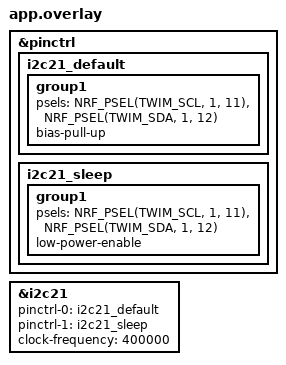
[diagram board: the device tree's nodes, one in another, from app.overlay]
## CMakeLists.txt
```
cmake_minimum_required(VERSION 3.20.0)

# Apply the device-tree overlay that enables I2C20 on P1.2/P1.3
list(APPEND EXTRA_DTC_OVERLAY_FILE "${CMAKE_CURRENT_SOURCE_DIR}/app.overlay")

find_package(Zephyr REQUIRED HINTS $ENV{ZEPHYR_BASE})

project(ThermalCam)

target_sources(app PRIVATE
  src/main.c
  src/mlx90640_api.c
  src/mlx90640_i2c.c
  src/ble_stream.c
)
```

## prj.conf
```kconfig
# UART logging — immediate (synchronous) mode prevents dropped messages
# when many lines are emitted back-to-back (e.g. the 31-line image frame).
CONFIG_LOG=y
CONFIG_LOG_BACKEND_UART=y
CONFIG_LOG_DEFAULT_LEVEL=4
CONFIG_LOG_MODE_IMMEDIATE=y

# Suppress noisy kernel mutex/scheduler debug traces from the 'os' module.
CONFIG_LOG_OVERRIDE_LEVEL=0
CONFIG_KERNEL_LOG_LEVEL_WRN=y

# Suppress BT stack / HCI / SoftDevice Controller debug traces.
CONFIG_BT_HCI_CORE_LOG_LEVEL_WRN=y
CONFIG_BT_HCI_DRIVER_LOG_LEVEL_WRN=y
CONFIG_BT_LOG_LEVEL_WRN=y

# Suppress CRACEN crypto driver power-on/off debug traces.
CONFIG_CRACEN_LOG_LEVEL_WRN=y

# GPIO for LED indicators
CONFIG_GPIO=y

# I2C driver for MLX90640
CONFIG_I2C=y

# Floating-point support (Cortex-M33 FPU)
CONFIG_FPU=y
CONFIG_FPU_SHARING=y

# Enable %f / %.1f in LOG_INF and printk
CONFIG_CBPRINTF_FP_SUPPORT=y

# ── BLE Nordic UART Service (NUS) ─────────────────────────────────────────
# BLE stack — Peripheral role (advertise + accept connections)
CONFIG_BT=y
CONFIG_BT_PERIPHERAL=y
CONFIG_BT_DEVICE_NAME="ThermalCam"
CONFIG_BT_DEVICE_APPEARANCE=0

# Nordic UART Service
CONFIG_BT_NUS=y

# Data Length Extension: up to 251-byte LL payload → 244-byte ATT payload
# This reduces the number of notifications per frame from 39 to 4.
CONFIG_BT_CTLR_DATA_LENGTH_MAX=251
CONFIG_BT_L2CAP_TX_MTU=247
CONFIG_BT_BUF_ACL_RX_SIZE=255
CONFIG_BT_BUF_ACL_TX_SIZE=255

# BLE callbacks run on the system workqueue — give it more stack
CONFIG_SYSTEM_WORKQUEUE_STACK_SIZE=4096
```

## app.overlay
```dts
/* Device tree overlay for ThermalCam on nRF54L15 DK (Nordic Semiconductor).
 *
 * Enables the I2C21 (TWIM1) peripheral on:
 *   SCL = P1.11
 *   SDA = P1.12
 *
 * Pin selection rationale (nRF54L15 DK):
 *   P0.0-P0.3  = UART30 (second UART)
 *   P0.4       = button3 / GRTC
 *   P1.4-P1.7  = UART20 (console)
 *   P1.8       = button2 / GRTC clkout
 *   P1.9       = button1
 *   P1.10      = LED1 / PWM20
 *   P1.13      = button0
 *   P1.14      = LED3
 *   P2.1/2/4   = SPI00 (NOR flash)
 *   P2.5       = SPI CS
 *   P2.7/2.9   = LEDs
 *   P1.2/P1.3  = ETM trace (TRACEDATA[2:3]) — require PCB modification
 *   P1.11/P1.12 = free general-purpose header pins, no board hardware attached
 *
 * The MLX90640 sensor is wired to these pins at I2C address 0x33.
 */

&pinctrl {
	i2c21_default: i2c21_default {
		group1 {
			psels = <NRF_PSEL(TWIM_SCL, 1, 11)>,
			        <NRF_PSEL(TWIM_SDA, 1, 12)>;
			bias-pull-up;
		};
	};

	i2c21_sleep: i2c21_sleep {
		group1 {
			psels = <NRF_PSEL(TWIM_SCL, 1, 11)>,
			        <NRF_PSEL(TWIM_SDA, 1, 12)>;
			low-power-enable;
		};
	};
};

&i2c21 {
	status = "okay";
	pinctrl-0 = <&i2c21_default>;
	pinctrl-1 = <&i2c21_sleep>;
	pinctrl-names = "default", "sleep";
	clock-frequency = <400000>;
};
```

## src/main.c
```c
/**
 * ThermalCam — MLX90640 thermal imaging on nRF54L15.
 *
 * Wiring: I2C20 on P1.2 (SCL) / P1.3 (SDA).  See app.overlay.
 * Sensor I2C address: 0x33 (MLX90640 default).
 *
 * The main() function configures the sensor once, then starts a periodic
 * thread that reads a thermal frame every MLX90640_READ_INTERVAL_S seconds
 * and renders it as an ASCII heat map on the RTT log.
 */

#include <zephyr/kernel.h>
#include <zephyr/device.h>
#include <zephyr/drivers/gpio.h>
#include <zephyr/logging/log.h>

#include "mlx90640_api.h"
#include "mlx90640_i2c.h"
#include "ble_stream.h"

LOG_MODULE_REGISTER(main, LOG_LEVEL_DBG);

/* The devicetree node identifier for the "led0"  and "led1" alias. */
#define LED0_NODE DT_ALIAS(led0)
#define LED1_NODE DT_ALIAS(led1)
#define LED2_NODE DT_ALIAS(led2)
#define LED3_NODE DT_ALIAS(led3)

/* ---- LED indicators ---- */
static const struct gpio_dt_spec s_led2 = GPIO_DT_SPEC_GET(LED2_NODE, gpios);
static const struct gpio_dt_spec s_led3 = GPIO_DT_SPEC_GET(LED3_NODE, gpios);

/* ---- Sensor settings ---- */
#define MLX90640_ADDR           0x33    /* Default 7-bit I2C address */
#define MLX90640_EMISSIVITY     0.95f   /* Typical for most surfaces */
#define MLX90640_TA_SHIFT       8.0f    /* °C shift applied to Ta for TR */
#define MLX90640_REFRESH_RATE    0x03    /* 4 Hz (register value) */
#define MLX90640_READ_INTERVAL_MS 500    /* Milliseconds between frame captures (2 fps) */

/* ---- Image geometry ---- */
#define MLX90640_ROWS    24
#define MLX90640_COLS    32
#define MLX90640_PIXELS  (MLX90640_ROWS * MLX90640_COLS)  /* 768 */

/*
 * Large buffers are static/global to keep them off the thread stack.
 * Combined they consume ~9.5 KB of BSS.
 */
static uint16_t       s_ee_data[832];
static uint16_t       s_frame_data[834];
static float          s_temp_image[MLX90640_PIXELS];
static paramsMLX90640 s_mlx90640_params;

/* ---- Thermal thread ---- */
#define THERMAL_STACK_SIZE  8192
#define THERMAL_PRIORITY    5

K_THREAD_STACK_DEFINE(s_thermal_stack, THERMAL_STACK_SIZE);
static struct k_thread s_thermal_thread;

/*
 * 7-level thermal palette — cold to hot:
 *   ' '  background / very cold
 *   '.'  cool
 *   '+'  below ambient
 *   '*'  near ambient
 *   'o'  warm
 *   '#'  hot
 *   '@'  very hot
 */
static const char ASCII_PALETTE[] = " .+*o#@";
#define ASCII_LEVELS ((int)(sizeof(ASCII_PALETTE) - 1))  /* 7 */

/* ============================================================
 * mlx90640_configure
 *
 * Obtains the I2C20 device, initialises the low-level driver,
 * dumps the sensor EEPROM, extracts calibration data, and sets
 * the refresh rate.
 *
 * Returns 0 on success, negative errno on failure.
 * ============================================================ */
static int mlx90640_configure(void)
{
    const struct device *i2c_dev = DEVICE_DT_GET(DT_NODELABEL(i2c21));

    if (!device_is_ready(i2c_dev)) {
        LOG_ERR("I2C21 device not ready");
        return -ENODEV;
    }

    MLX90640_I2CInit(i2c_dev);
    LOG_INF("I2C21 initialised (SCL=P1.11 SDA=P1.12, 400 kHz)");

    /* Read the 832-word factory calibration EEPROM. */
    int ret = MLX90640_DumpEE(MLX90640_ADDR, s_ee_data);
    if (ret != 0) {
        LOG_ERR("Failed to dump EEPROM (err %d)", ret);
        return ret;
    }
    LOG_INF("EEPROM read OK");

    /* Parse EEPROM into per-pixel calibration parameters. */
    ret = MLX90640_ExtractParameters(s_ee_data, &s_mlx90640_params);
    if (ret != 0) {
        LOG_ERR("Parameter extraction failed (err %d)", ret);
        return ret;
    }
    LOG_INF("Calibration parameters extracted");

    /* Set hardware refresh rate to 16 Hz (register value 0x05). */
    ret = MLX90640_SetRefreshRate(MLX90640_ADDR, MLX90640_REFRESH_RATE);
    if (ret != 0) {
        LOG_ERR("Failed to set refresh rate (err %d)", ret);
        return ret;
    }
    LOG_INF("MLX90640 configured: 4 Hz refresh, emissivity=0.95");

    return 0;
}

/* ============================================================
 * mlx90640_read_image
 *
 * Reads two consecutive sub-frames (interleaved/chess mode).
 * After both sub-frames, s_temp_image[] holds temperatures for
 * all 768 pixels (24 rows × 32 columns), in °C.
 *
 * Returns 0 on success, negative on I2C or sensor error.
 * ============================================================ */
#define SUBFRAME_MAX_RETRIES  3

static int mlx90640_read_image(void)
{
    for (int subframe = 0; subframe < 2; subframe++) {
        int ret = -1;

        for (int attempt = 0; attempt < SUBFRAME_MAX_RETRIES; attempt++) {
            ret = MLX90640_GetFrameData(MLX90640_ADDR, s_frame_data);
            if (ret >= 0) {
                break;  /* success */
            }
            LOG_WRN("GetFrameData failed (sub %d, attempt %d, err %d)",
                    subframe, attempt, ret);

            /* Try to unstick the I2C bus before retrying. */
            (void)MLX90640_I2CRecover();
            k_msleep(50);
        }

        if (ret < 0) {
            LOG_ERR("GetFrameData failed after %d retries (sub %d, err %d)",
                    SUBFRAME_MAX_RETRIES, subframe, ret);
            return ret;
        }

        float vdd = MLX90640_GetVdd(s_frame_data, &s_mlx90640_params);
        float ta  = MLX90640_GetTa(s_frame_data,  &s_mlx90640_params);
        float tr  = ta - MLX90640_TA_SHIFT;   /* reflected temperature */

        MLX90640_CalculateTo(s_frame_data, &s_mlx90640_params,
                             MLX90640_EMISSIVITY, tr, s_temp_image);

        LOG_DBG("Sub-frame %d: VDD=%.2fV  Ta=%.1f°C  TR=%.1f°C",
                subframe, (double)vdd, (double)ta, (double)tr);
    }

    return 0;
}

/* ============================================================
 * mlx90640_display_ascii
 *
 * Maps the 768-pixel temperature array onto a 92-level greyscale
 * ASCII ramp and prints it via the UART logging back-end.
 *
 * Statistics printed:
 *   min  – coldest pixel temperature (°C)
 *   max  – hottest pixel temperature (°C)
 *   mean – average pixel temperature (°C)
 *   span – max − min (°C)
 *
 * Layout: 24 rows × 32 characters, bordered with '|' pipes.
 * ============================================================ */
static void mlx90640_display_ascii(void)
{
    /* ---- Compute statistics ---- */
    float t_min  = s_temp_image[0];
    float t_max  = s_temp_image[0];
    float t_sum  = 0.0f;

    for (int i = 0; i < MLX90640_PIXELS; i++) {
        float t = s_temp_image[i];
        if (t < t_min) { t_min = t; }
        if (t > t_max) { t_max = t; }
        t_sum += t;
    }

    float t_mean  = t_sum / (float)MLX90640_PIXELS;
    float t_span  = t_max - t_min;
    if (t_span < 0.1f) {
        t_span = 0.1f;   /* guard against flat scenes */
    }

    /* ---- Header with statistics ---- */
    LOG_INF("+--------------------------------+");
    LOG_INF("| MLX90640  %3d x %2d  greyscale  |",
            MLX90640_COLS, MLX90640_ROWS);
    LOG_INF("| min  %6d.%01d C                  |",
            (int)t_min,  (int)((t_min  < 0 ? -t_min  : t_min)  * 10) % 10);
    LOG_INF("| max  %6d.%01d C                  |",
            (int)t_max,  (int)((t_max  < 0 ? -t_max  : t_max)  * 10) % 10);
    LOG_INF("| mean %6d.%01d C                  |",
            (int)t_mean, (int)((t_mean < 0 ? -t_mean : t_mean) * 10) % 10);
    LOG_INF("| span %6d.%01d C                  |",
            (int)t_span, (int)(t_span * 10) % 10);
    LOG_INF("+--------------------------------+");

    /* ---- Image rows ---- */
    /* Row buffer: '|' + 32 chars + '|' + '\0' */
    char row_buf[MLX90640_COLS + 3];
    row_buf[0]                 = '|';
    row_buf[MLX90640_COLS + 1] = '|';
    row_buf[MLX90640_COLS + 2] = '\0';

    for (int row = 0; row < MLX90640_ROWS; row++) {
        for (int col = 0; col < MLX90640_COLS; col++) {
            float t = s_temp_image[row * MLX90640_COLS + col];
            int level = (int)((t - t_min) / t_span * (float)(ASCII_LEVELS - 1));

            if (level < 0)             { level = 0; }
            if (level >= ASCII_LEVELS) { level = ASCII_LEVELS - 1; }

            row_buf[col + 1] = ASCII_PALETTE[level];
        }
        LOG_INF("%s", row_buf);
    }

    LOG_INF("+--------------------------------+");
}

/* ============================================================
 * Thermal thread entry point
 * ============================================================ */
static void thermal_thread_fn(void *p1, void *p2, void *p3)
{
    ARG_UNUSED(p1);
    ARG_UNUSED(p2);
    ARG_UNUSED(p3);

    while (true) {
        gpio_pin_set_dt(&s_led2, 1);
        int ret = mlx90640_read_image();
        gpio_pin_set_dt(&s_led2, 0);

        if (ret == 0) {
            mlx90640_display_ascii();
            gpio_pin_set_dt(&s_led3, 1);
            ble_stream_send_frame(s_temp_image, MLX90640_PIXELS);
            gpio_pin_set_dt(&s_led3, 0);
        } else {
            LOG_ERR("Image read failed (err %d) — retrying in %d ms",
                    ret, MLX90640_READ_INTERVAL_MS);
        }

        k_sleep(K_MSEC(MLX90640_READ_INTERVAL_MS));
    }
}

/* ============================================================
 * main
 * ============================================================ */
int main(void)
{
    LOG_INF("ThermalCam starting (nRF54L15 + MLX90640)");

    /* Configure LED2 (capture) and LED3 (BLE TX) as outputs, initially off. */
    if (gpio_is_ready_dt(&s_led2)) {
        gpio_pin_configure_dt(&s_led2, GPIO_OUTPUT_INACTIVE);
    }
    if (gpio_is_ready_dt(&s_led3)) {
        gpio_pin_configure_dt(&s_led3, GPIO_OUTPUT_INACTIVE);
    }

    int ret = ble_stream_init();
    if (ret != 0) {
        LOG_ERR("BLE init failed (err %d) — continuing without BLE", ret);
    }

    ret = mlx90640_configure();
    if (ret != 0) {
        LOG_ERR("Sensor configuration failed (err %d) — halting", ret);
        return ret;
    }

    k_thread_create(&s_thermal_thread,
                    s_thermal_stack, K_THREAD_STACK_SIZEOF(s_thermal_stack),
                    thermal_thread_fn, NULL, NULL, NULL,
                    THERMAL_PRIORITY, 0, K_NO_WAIT);

    k_thread_name_set(&s_thermal_thread, "thermal");

    LOG_INF("Thermal imaging thread started (reads every %d ms)",
            MLX90640_READ_INTERVAL_MS);

    return 0;
}
```

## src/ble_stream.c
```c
/**
 * ble_stream.c — BLE NUS thermal frame streaming for ThermalCam.
 *
 * See ble_stream.h for the wire-protocol description.
 *
 * SPDX-License-Identifier: Apache-2.0
 */

#include <zephyr/kernel.h>
#include <zephyr/drivers/gpio.h>
#include <zephyr/bluetooth/bluetooth.h>
#include <zephyr/bluetooth/conn.h>
#include <bluetooth/services/nus.h>
#include <zephyr/logging/log.h>

#include "ble_stream.h"

LOG_MODULE_REGISTER(ble_stream, LOG_LEVEL_INF);

/* ---- Frame geometry ---- */
#define FRAME_ROWS    24
#define FRAME_COLS    32
#define FRAME_PIXELS  (FRAME_ROWS * FRAME_COLS)              /* 768  */
#define FRAME_BUF_SZ  (2 + 2 + 2 + FRAME_PIXELS + 2)        /* 776  */

/* ---- LED0: BLE connected indicator ---- */
static const struct gpio_dt_spec s_led0 = GPIO_DT_SPEC_GET(DT_ALIAS(led0), gpios);

/* ---- Module-level state ---- */
static struct bt_conn *s_conn;          /* NULL when not connected */
static bool           s_notify_enabled; /* true once peer writes CCCD = 1 */
static K_SEM_DEFINE(s_bt_ready, 0, 1); /* signalled by bt_ready_cb */

/* Work item to restart advertising outside the BT RX thread context. */
static void adv_restart_work_handler(struct k_work *work);
static K_WORK_DEFINE(s_adv_restart_work, adv_restart_work_handler);

/* ---- Advertising / scan-response data ---------------------------------- */

/*
 * Primary advertisement: flags + NUS service UUID.
 * The NUS UUID in the ad payload lets the Python bleak scanner (and nRF
 * Connect for Mobile) identify the device by service, not just name.
 */
static const struct bt_data s_adv[] = {
    BT_DATA_BYTES(BT_DATA_FLAGS, (BT_LE_AD_GENERAL | BT_LE_AD_NO_BREDR)),
    BT_DATA_BYTES(BT_DATA_UUID128_ALL, BT_UUID_NUS_VAL),
};

/*
 * Scan response: device name.
 * Splitting name into the scan response keeps the primary ad short while
 * still letting the PC identify the device by the "ThermalCam" name.
 */
static const struct bt_data s_sd[] = {
    BT_DATA(BT_DATA_NAME_COMPLETE,
            CONFIG_BT_DEVICE_NAME, sizeof(CONFIG_BT_DEVICE_NAME) - 1),
};

/* ---- BT controller-ready callback -------------------------------------- */

static void bt_ready_cb(int err)
{
    if (err) {
        LOG_ERR("bt_enable failed (err %d)", err);
        return;
    }
    k_sem_give(&s_bt_ready);
}

/* ---- Advertising restart (runs on system workqueue) -------------------- */

static void adv_restart_work_handler(struct k_work *work)
{
    int ret = bt_le_adv_start(BT_LE_ADV_CONN_FAST_1,
                              s_adv, ARRAY_SIZE(s_adv),
                              s_sd,  ARRAY_SIZE(s_sd));
    if (ret) {
        LOG_ERR("Advertising restart failed (err %d)", ret);
    } else {
        LOG_INF("Re-advertising as \"%s\"", CONFIG_BT_DEVICE_NAME);
    }
}

/* ---- Connection event callbacks ---------------------------------------- */

static void connected_cb(struct bt_conn *conn, uint8_t err)
{
    if (err) {
        LOG_ERR("Connection failed (err 0x%02x)", err);
        return;
    }
    s_conn = bt_conn_ref(conn);
    gpio_pin_set_dt(&s_led0, 1);
    LOG_INF("BLE peer connected");
}

static void nus_send_enabled_cb(enum bt_nus_send_status status)
{
    s_notify_enabled = (status == BT_NUS_SEND_STATUS_ENABLED);
    LOG_INF("NUS notifications %s",
            s_notify_enabled ? "enabled" : "disabled");
}

static void disconnected_cb(struct bt_conn *conn, uint8_t reason)
{
    LOG_INF("BLE peer disconnected (reason 0x%02x)", reason);

    gpio_pin_set_dt(&s_led0, 0);
    s_notify_enabled = false;

    if (s_conn) {
        bt_conn_unref(s_conn);
        s_conn = NULL;
    }

    /* Defer advertising restart to the system workqueue so it runs
     * outside the BT RX thread context (avoids a silent failure on
     * some nRF Connect SDK versions). */
    k_work_submit(&s_adv_restart_work);
}

BT_CONN_CB_DEFINE(conn_callbacks) = {
    .connected    = connected_cb,
    .disconnected = disconnected_cb,
};

/* ============================================================
 * ble_stream_init
 * ============================================================ */
int ble_stream_init(void)
{
    /* Configure LED0 (BLE connected indicator), initially off. */
    if (gpio_is_ready_dt(&s_led0)) {
        gpio_pin_configure_dt(&s_led0, GPIO_OUTPUT_INACTIVE);
    }

    /* Enable the BT controller; bt_ready_cb fires when ready. */
    int ret = bt_enable(bt_ready_cb);
    if (ret) {
        LOG_ERR("bt_enable failed (err %d)", ret);
        return ret;
    }
    k_sem_take(&s_bt_ready, K_FOREVER);
    LOG_INF("BT stack ready");

    /* Register NUS callbacks. */
    static struct bt_nus_cb nus_cb = {
        .send_enabled = nus_send_enabled_cb,
    };
    ret = bt_nus_init(&nus_cb);
    if (ret) {
        LOG_ERR("NUS init failed (err %d)", ret);
        return ret;
    }

    /* Start advertising. */
    ret = bt_le_adv_start(BT_LE_ADV_CONN_FAST_1,
                          s_adv, ARRAY_SIZE(s_adv),
                          s_sd,  ARRAY_SIZE(s_sd));
    if (ret) {
        LOG_ERR("Advertising start failed (err %d)", ret);
        return ret;
    }

    LOG_INF("Advertising as \"%s\"", CONFIG_BT_DEVICE_NAME);
    return 0;
}

/* ============================================================
 * ble_stream_send_frame
 * ============================================================ */
void ble_stream_send_frame(const float *temp_image, int n_pixels)
{
    if (!s_conn) {
        LOG_DBG("No BLE peer connected — skipping frame");
        return;
    }

    if (!s_notify_enabled) {
        LOG_DBG("NUS notifications not yet enabled — skipping frame");
        return;
    }

    /* ---- Compute min / max over all pixels ---- */
    float t_min = temp_image[0];
    float t_max = temp_image[0];

    for (int i = 1; i < n_pixels; i++) {
        if (temp_image[i] < t_min) { t_min = temp_image[i]; }
        if (temp_image[i] > t_max) { t_max = temp_image[i]; }
    }

    float t_span = t_max - t_min;
    if (t_span < 0.1f) {
        t_span = 0.1f;   /* guard against a completely flat scene */
    }

    /* ---- Assemble the 776-byte frame (static — kept off the stack) ---- */
    static uint8_t buf[FRAME_BUF_SZ];

    /* SOF */
    buf[0] = 0xFF;
    buf[1] = 0xFE;

    /* t_min × 10 and t_max × 10 as big-endian int16_t */
    int16_t t_min_x10 = (int16_t)(t_min * 10.0f);
    int16_t t_max_x10 = (int16_t)(t_max * 10.0f);

    buf[2] = (uint8_t)((uint16_t)t_min_x10 >> 8);
    buf[3] = (uint8_t)((uint16_t)t_min_x10 & 0xFF);
    buf[4] = (uint8_t)((uint16_t)t_max_x10 >> 8);
    buf[5] = (uint8_t)((uint16_t)t_max_x10 & 0xFF);

    /* Greyscale pixels: 0 = coldest, 255 = hottest */
    for (int i = 0; i < n_pixels; i++) {
        float v = (temp_image[i] - t_min) / t_span * 255.0f;

        if (v <   0.0f) { v =   0.0f; }
        if (v > 255.0f) { v = 255.0f; }

        buf[6 + i] = (uint8_t)v;
    }

    /* EOF at fixed offset 774 */
    buf[6 + n_pixels]     = 0xFF;
    buf[6 + n_pixels + 1] = 0xFD;

    /* ---- Send in MTU-sized chunks via NUS TX notifications ---- */
    uint32_t mtu = bt_nus_get_mtu(s_conn);
    if (mtu == 0) {
        mtu = 20;  /* conservative fallback if MTU exchange has not occurred */
    }

    for (size_t offset = 0; offset < FRAME_BUF_SZ; ) {
        size_t chunk = MIN(mtu, (uint32_t)(FRAME_BUF_SZ - offset));
        int ret = bt_nus_send(s_conn, buf + offset, (uint16_t)chunk);

        if (ret) {
            LOG_ERR("bt_nus_send failed at offset %zu (err %d)", offset, ret);
            return;
        }
        offset += chunk;
    }

    LOG_INF("BLE frame sent (%d B)  min=%.1f C  max=%.1f C",
            FRAME_BUF_SZ, (double)t_min, (double)t_max);
}
```

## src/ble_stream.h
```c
/**
 * ble_stream.h — BLE Nordic UART Service (NUS) thermal frame streaming.
 *
 * Call ble_stream_init() once from main(), then call
 * ble_stream_send_frame() after each captured thermal image.
 *
 * Wire protocol (776 bytes per frame, big-endian integers):
 *
 *   Offset  Size  Content
 *        0     2  SOF  0xFF 0xFE
 *        2     2  t_min × 10  (int16_t BE)  — e.g. 227 = 22.7 °C
 *        4     2  t_max × 10  (int16_t BE)
 *        6   768  pixels[0..767]  uint8  0 = coldest, 255 = hottest
 *      774     2  EOF  0xFF 0xFD
 *
 * EOF is checked at the fixed offset 774 (not searched), so pixel data
 * that happens to contain the SOF byte pattern does not cause framing
 * errors on the receiver.
 *
 * SPDX-License-Identifier: Apache-2.0
 */

#ifndef BLE_STREAM_H
#define BLE_STREAM_H

/**
 * @brief Initialise the BT stack, register NUS, and start advertising
 *        as CONFIG_BT_DEVICE_NAME ("ThermalCam").
 *
 * Blocks until the BT controller signals readiness.  Safe to call once
 * from main() before starting the thermal thread.
 *
 * @return 0 on success, negative errno on failure.
 */
int ble_stream_init(void);

/**
 * @brief Encode and transmit one 32 × 24 thermal frame over BLE NUS.
 *
 * Normalises pixel temperatures to uint8 greyscale 0–255, prepends a
 * 4-byte header (t_min, t_max, both × 10 as int16_t BE), wraps in
 * SOF/EOF markers, and sends in MTU-sized chunks.  No-op when no BLE
 * peer is connected.
 *
 * @param temp_image  Array of @p n_pixels float temperatures in °C,
 *                    stored row-major (32 columns × 24 rows).
 * @param n_pixels    Number of pixels — must be 768 (MLX90640_PIXELS).
 */
void ble_stream_send_frame(const float *temp_image, int n_pixels);

#endif /* BLE_STREAM_H */
```

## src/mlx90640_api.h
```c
/**
 * MLX90640 API - Pure C port of the Melexis MLX90640 driver.
 *
 * Original: Copyright (C) 2017 Melexis N.V.
 * Ported for Zephyr / nRF54L15.
 *
 * SPDX-License-Identifier: Apache-2.0
 */

#ifndef MLX90640_API_H
#define MLX90640_API_H

#include <stdint.h>

/**
 * @brief Calibration and configuration parameters extracted from the sensor EEPROM.
 *
 * All 768 pixels (24 rows × 32 columns) have individual calibration entries.
 */
typedef struct {
    /* Supply voltage parameters */
    int16_t kVdd;
    int16_t vdd25;

    /* PTAT (proportional-to-absolute-temperature) sensor parameters */
    float KvPTAT;
    float KtPTAT;
    uint16_t vPTAT25;
    float alphaPTAT;

    /* Gain */
    int16_t gainEE;

    /* Thermal gradient coefficient */
    float tgc;

    /* Compensation pixel coefficients */
    float cpKv;
    float cpKta;

    /* Resolution and calibration mode */
    uint8_t resolutionEE;
    uint8_t calibrationModeEE;

    /* Temperature sensitivity coefficients */
    float KsTa;
    float ksTo[4];
    int16_t ct[4];

    /* Per-pixel calibration arrays (768 pixels) */
    float   alpha[768];
    int16_t offset[768];
    float   kta[768];
    float   kv[768];

    /* Compensation pixel data */
    float   cpAlpha[2];
    int16_t cpOffset[2];

    /* Interleaved/Chess correction coefficients */
    float ilChessC[3];

    /* Defective pixel indices (0xFFFF = unused slot) */
    uint16_t brokenPixels[5];
    uint16_t outlierPixels[5];
} paramsMLX90640;

/* ---- I/O functions ---- */

/** Read 832 EEPROM words into eeData. Returns 0 on success, negative on error. */
int MLX90640_DumpEE(uint8_t slaveAddr, uint16_t *eeData);

/**
 * Read one frame of raw IR data (834 words) from the sensor.
 * Returns the sub-page number (0 or 1) on success, negative on error.
 */
int MLX90640_GetFrameData(uint8_t slaveAddr, uint16_t *frameData);

/**
 * Parse EEPROM words into calibration parameters.
 * Returns 0 on success, negative on error.
 */
int MLX90640_ExtractParameters(uint16_t *eeData, paramsMLX90640 *mlx90640);

/* ---- Calculation functions ---- */

/** Return the supply voltage (VDD) measured during the last frame. */
float MLX90640_GetVdd(uint16_t *frameData, const paramsMLX90640 *params);

/** Return the ambient temperature (Ta, °C) measured during the last frame. */
float MLX90640_GetTa(uint16_t *frameData, const paramsMLX90640 *params);

/**
 * Convert raw frame data to absolute pixel temperatures (°C).
 *
 * @param frameData  834-word buffer from MLX90640_GetFrameData().
 * @param params     Calibration parameters from MLX90640_ExtractParameters().
 * @param emissivity Object emissivity (typically 0.95).
 * @param tr         Reflected ambient temperature = Ta - TA_SHIFT.
 * @param result     Output buffer for 768 temperatures (24×32 pixels, °C).
 */
void MLX90640_CalculateTo(uint16_t *frameData, const paramsMLX90640 *params,
                          float emissivity, float tr, float *result);

/**
 * Produce a compensated IR image (without absolute temperature conversion).
 * Useful for relative heat mapping.
 */
void MLX90640_GetImage(uint16_t *frameData, const paramsMLX90640 *params,
                       float *result);

/* ---- Configuration functions ---- */

int MLX90640_SetResolution(uint8_t slaveAddr, uint8_t resolution);
int MLX90640_GetCurResolution(uint8_t slaveAddr);
int MLX90640_SetRefreshRate(uint8_t slaveAddr, uint8_t refreshRate);
int MLX90640_GetRefreshRate(uint8_t slaveAddr);
int MLX90640_GetSubPageNumber(uint16_t *frameData);
int MLX90640_GetCurMode(uint8_t slaveAddr);
int MLX90640_SetInterleavedMode(uint8_t slaveAddr);
int MLX90640_SetChessMode(uint8_t slaveAddr);

#endif /* MLX90640_API_H */
```

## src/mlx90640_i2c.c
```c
/**
 * MLX90640 I2C driver — Zephyr TWIM implementation.
 *
 * Implements the low-level I2C transfers required by mlx90640_api.c using
 * Zephyr's I2C API (i2c_write_read / i2c_write).
 *
 * The MLX90640 uses 16-bit register addresses and sends data MSB-first
 * over I2C. Byte order is fixed up after each read.
 *
 * SPDX-License-Identifier: Apache-2.0
 */

#include <zephyr/drivers/i2c.h>
#include <zephyr/sys/byteorder.h>
#include <zephyr/logging/log.h>

#include "mlx90640_i2c.h"

LOG_MODULE_REGISTER(mlx90640_i2c, LOG_LEVEL_DBG);

static const struct device *s_i2c_dev;

void MLX90640_I2CInit(const struct device *i2c_device)
{
    s_i2c_dev = i2c_device;
}

int MLX90640_I2CRead(uint8_t slaveAddr, unsigned int startAddress,
                     unsigned int nWordsRead, uint16_t *data)
{
    uint8_t addr_buf[2] = {
        (uint8_t)(startAddress >> 8),
        (uint8_t)(startAddress & 0xFF)
    };

    /* Single combined write-then-read transfer (repeated START on the wire). */
    int ret = i2c_write_read(s_i2c_dev, (uint16_t)slaveAddr,
                             addr_buf, sizeof(addr_buf),
                             (uint8_t *)data, nWordsRead * 2U);
    if (ret != 0) {
        LOG_ERR("I2C read from addr 0x%04X failed: %d", startAddress, ret);
        return ret;
    }

    /*
     * The sensor sends each 16-bit word MSB-first (big-endian).
     * After the raw byte read, data[i] holds bytes [MSB, LSB] in memory,
     * which a little-endian CPU interprets as (LSB | MSB<<8) — wrong.
     * sys_be16_to_cpu() byte-swaps to give the correct value.
     */
    for (unsigned int i = 0; i < nWordsRead; i++) {
        data[i] = sys_be16_to_cpu(data[i]);
    }

    return 0;
}

int MLX90640_I2CWrite(uint8_t slaveAddr, unsigned int writeAddress, uint16_t data)
{
    uint8_t buf[4] = {
        (uint8_t)(writeAddress >> 8),
        (uint8_t)(writeAddress & 0xFF),
        (uint8_t)(data >> 8),
        (uint8_t)(data & 0xFF)
    };

    int ret = i2c_write(s_i2c_dev, buf, sizeof(buf), (uint16_t)slaveAddr);
    if (ret != 0) {
        LOG_ERR("I2C write to addr 0x%04X failed: %d", writeAddress, ret);
        return -1;
    }

    /* Verify the write by reading back and comparing. */
    uint16_t data_check;

    ret = MLX90640_I2CRead(slaveAddr, writeAddress, 1, &data_check);
    if (ret != 0) {
        return ret;
    }

    if (data_check != data) {
        /* A mismatch on a volatile/write-clear register (e.g. 0x8000) is
         * expected — the sensor updates it autonomously between the write
         * and the readback.  The caller decides whether -2 is fatal. */
        LOG_DBG("Write verify at 0x%04X: wrote 0x%04X, read 0x%04X (volatile reg, normal)",
                writeAddress, data, data_check);
        return -2;
    }

    return 0;
}

int MLX90640_I2CRecover(void)
{
    if (!s_i2c_dev) {
        return -ENODEV;
    }
    return i2c_recover_bus(s_i2c_dev);
}
```

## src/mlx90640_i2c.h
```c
/**
 * MLX90640 I2C driver interface for Zephyr.
 *
 * Wraps the Zephyr I2C API to match the MLX90640 low-level driver
 * interface expected by mlx90640_api.c.
 *
 * SPDX-License-Identifier: Apache-2.0
 */

#ifndef MLX90640_I2C_H
#define MLX90640_I2C_H

#include <stdint.h>
#include <zephyr/device.h>

/**
 * @brief Initialise the I2C driver with the given Zephyr I2C device.
 *
 * Must be called once before any other MLX90640_I2C* function.
 * The device must already be ready (device_is_ready() == true).
 */
void MLX90640_I2CInit(const struct device *i2c_device);

/**
 * @brief Read @p nWordsRead 16-bit words (big-endian on wire) from @p startAddress.
 *
 * @return 0 on success, negative errno on I2C error.
 */
int MLX90640_I2CRead(uint8_t slaveAddr, unsigned int startAddress,
                     unsigned int nWordsRead, uint16_t *data);

/**
 * @brief Write a single 16-bit word to @p writeAddress, then read back to verify.
 *
 * @return  0 on success.
 * @return -1 if the I2C write failed (no ACK).
 * @return -2 if the readback value does not match the written value.
 */
int MLX90640_I2CWrite(uint8_t slaveAddr, unsigned int writeAddress, uint16_t data);

/**
 * @brief Attempt to recover the I2C bus (toggle SCL to release a stuck SDA).
 *
 * @return 0 on success, negative errno on failure.
 */
int MLX90640_I2CRecover(void);

#endif /* MLX90640_I2C_H */
```
